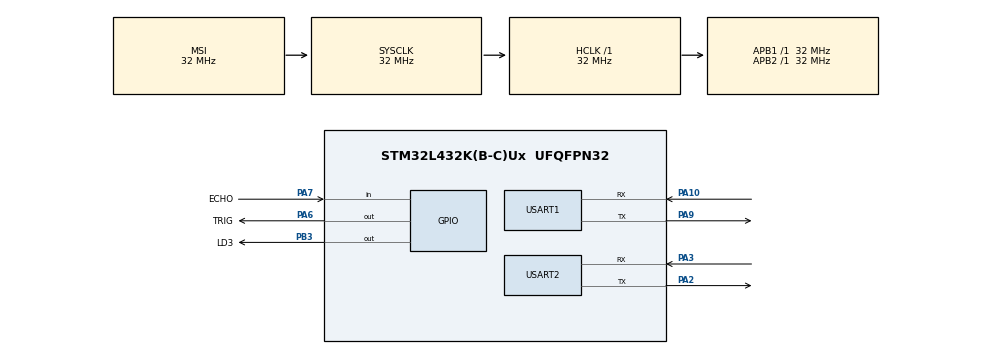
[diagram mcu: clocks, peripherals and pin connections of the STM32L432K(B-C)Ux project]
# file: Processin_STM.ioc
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Mcu.Family=STM32L4
Mcu.Name=STM32L432K(B-C)Ux
Mcu.Package=UFQFPN32
NVIC.PriorityGroup=NVIC_PRIORITYGROUP_4
NVIC.USART2_IRQn=true\:0\:0\:false\:false\:true\:true\:true\:true
PA10.Mode=Asynchronous
PA10.Signal=USART1_RX
PA2.Mode=Asynchronous
PA2.Signal=USART2_TX
PA3.Mode=Asynchronous
PA3.Signal=USART2_RX
PA6.GPIO_Label=TRIG
PA6.Signal=GPIO_Output
PA7.GPIO_Label=ECHO
PA7.Signal=GPIO_Input
PA9.Mode=Asynchronous
PA9.Signal=USART1_TX
PB3\ (JTDO-TRACESWO).GPIO_Label=LD3
PB3\ (JTDO-TRACESWO).Signal=GPIO_Output
ProjectManager.HeapSize=0x200
ProjectManager.StackSize=0x400
ProjectManager.TargetToolchain=CMake
RCC.ADCFreq_Value=128000000
RCC.AHBFreq_Value=32000000
RCC.APB1Freq_Value=32000000
RCC.APB1TimFreq_Value=32000000
RCC.APB2Freq_Value=32000000
RCC.APB2TimFreq_Value=32000000
RCC.CortexFreq_Value=32000000
RCC.HCLKFreq_Value=32000000
RCC.HSE_VALUE=8000000
RCC.HSI48_VALUE=48000000
RCC.HSI_VALUE=16000000
RCC.LSE_VALUE=32768
RCC.MSIClockRange=RCC_MSIRANGE_10
RCC.MSI_VALUE=32000000
RCC.SYSCLKFreq_VALUE=32000000
RCC.USBFreq_Value=128000000
RCC.VCOOutputFreq_Value=256000000
TIM16.Prescaler=31
USART1.VirtualMode-Asynchronous=VM_ASYNC
USART2.VirtualMode-Asynchronous=VM_ASYNC
VP_TIM16_VS_ClockSourceINT.Mode=Enable_Timer
board=custom

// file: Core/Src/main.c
/* USER CODE BEGIN Header */
/**
  ******************************************************************************
  * @file           : main.c
  * @brief          : Main program body
  ******************************************************************************
  * @attention
  *
  * Copyright (c) 2026 STMicroelectronics.
  * All rights reserved.
  *
  * This software is licensed under terms that can be found in the LICENSE file
  * in the root directory of this software component.
  * If no LICENSE file comes with this software, it is provided AS-IS.
  *
  ******************************************************************************
  */
/* USER CODE END Header */
#include "main.h"

/* USER CODE BEGIN Includes */
#include <stdio.h>
#include <string.h>
#include <math.h>
/* USER CODE END Includes */

TIM_HandleTypeDef htim16;

UART_HandleTypeDef huart1;
UART_HandleTypeDef huart2;

void SystemClock_Config(void);
static void MX_GPIO_Init(void);
static void MX_TIM16_Init(void);
static void MX_USART2_UART_Init(void);
static void MX_USART1_UART_Init(void);

int main(void)
{

  /* MCU Configuration--------------------------------------------------------*/

  /* Reset of all peripherals, Initializes the Flash interface and the Systick. */
  HAL_Init();

  /* Configure the system clock */
  SystemClock_Config();

  /* Initialize all configured peripherals */
  MX_GPIO_Init();
  MX_TIM16_Init();
  MX_USART2_UART_Init();
  MX_USART1_UART_Init();
  /* USER CODE BEGIN 2 */
  uint8_t buf[3];
  buf[0] = 128;
  buf[1] = 128;
  uint8_t mean;
  /* USER CODE END 2 */

  /* Infinite loop */
  while (1)
  {
    if (HAL_UART_Receive(&huart1, &buf[2], 1, HAL_MAX_DELAY) == HAL_OK)
    {
        buf[0] = buf[1];
        buf[1] = buf[2];
        mean = (buf[1] + buf[0]) / 2;
        HAL_UART_Transmit(&huart2, &mean, 1, HAL_MAX_DELAY);
    }
  }
}
  /* USER CODE END 3 */

void SystemClock_Config(void)
{
  RCC_OscInitTypeDef RCC_OscInitStruct = {0};
  RCC_ClkInitTypeDef RCC_ClkInitStruct = {0};

  /** Configure the main internal regulator output voltage
  */
  if (HAL_PWREx_ControlVoltageScaling(PWR_REGULATOR_VOLTAGE_SCALE1) != HAL_OK)
  {
    Error_Handler();
  }

  /** Initializes the RCC Oscillators according to the specified parameters
  * in the RCC_OscInitTypeDef structure.
  */
  RCC_OscInitStruct.OscillatorType = RCC_OSCILLATORTYPE_MSI;
  RCC_OscInitStruct.MSIState = RCC_MSI_ON;
  RCC_OscInitStruct.MSICalibrationValue = 0;
  RCC_OscInitStruct.MSIClockRange = RCC_MSIRANGE_10;
  RCC_OscInitStruct.PLL.PLLState = RCC_PLL_NONE;
  if (HAL_RCC_OscConfig(&RCC_OscInitStruct) != HAL_OK)
  {
    Error_Handler();
  }

  /** Initializes the CPU, AHB and APB buses clocks
  */
  RCC_ClkInitStruct.ClockType = RCC_CLOCKTYPE_HCLK|RCC_CLOCKTYPE_SYSCLK
                              |RCC_CLOCKTYPE_PCLK1|RCC_CLOCKTYPE_PCLK2;
  RCC_ClkInitStruct.SYSCLKSource = RCC_SYSCLKSOURCE_MSI;
  RCC_ClkInitStruct.AHBCLKDivider = RCC_SYSCLK_DIV1;
  RCC_ClkInitStruct.APB1CLKDivider = RCC_HCLK_DIV1;
  RCC_ClkInitStruct.APB2CLKDivider = RCC_HCLK_DIV1;

  if (HAL_RCC_ClockConfig(&RCC_ClkInitStruct, FLASH_LATENCY_1) != HAL_OK)
  {
    Error_Handler();
  }
}

static void MX_TIM16_Init(void)
{

  htim16.Instance = TIM16;
  htim16.Init.Prescaler = 31;
  htim16.Init.CounterMode = TIM_COUNTERMODE_UP;
  htim16.Init.Period = 65535;
  htim16.Init.ClockDivision = TIM_CLOCKDIVISION_DIV1;
  htim16.Init.RepetitionCounter = 0;
  htim16.Init.AutoReloadPreload = TIM_AUTORELOAD_PRELOAD_DISABLE;
  if (HAL_TIM_Base_Init(&htim16) != HAL_OK)
  {
    Error_Handler();
  }

}

static void MX_USART1_UART_Init(void)
{

  huart1.Instance = USART1;
  huart1.Init.BaudRate = 115200;
  huart1.Init.WordLength = UART_WORDLENGTH_8B;
  huart1.Init.StopBits = UART_STOPBITS_1;
  huart1.Init.Parity = UART_PARITY_NONE;
  huart1.Init.Mode = UART_MODE_TX_RX;
  huart1.Init.HwFlowCtl = UART_HWCONTROL_NONE;
  huart1.Init.OverSampling = UART_OVERSAMPLING_16;
  huart1.Init.OneBitSampling = UART_ONE_BIT_SAMPLE_DISABLE;
  huart1.AdvancedInit.AdvFeatureInit = UART_ADVFEATURE_NO_INIT;
  if (HAL_UART_Init(&huart1) != HAL_OK)
  {
    Error_Handler();
  }

}

static void MX_USART2_UART_Init(void)
{

  huart2.Instance = USART2;
  huart2.Init.BaudRate = 115200;
  huart2.Init.WordLength = UART_WORDLENGTH_8B;
  huart2.Init.StopBits = UART_STOPBITS_1;
  huart2.Init.Parity = UART_PARITY_NONE;
  huart2.Init.Mode = UART_MODE_TX_RX;
  huart2.Init.HwFlowCtl = UART_HWCONTROL_NONE;
  huart2.Init.OverSampling = UART_OVERSAMPLING_16;
  huart2.Init.OneBitSampling = UART_ONE_BIT_SAMPLE_DISABLE;
  huart2.AdvancedInit.AdvFeatureInit = UART_ADVFEATURE_NO_INIT;
  if (HAL_UART_Init(&huart2) != HAL_OK)
  {
    Error_Handler();
  }

}

static void MX_GPIO_Init(void)
{
  GPIO_InitTypeDef GPIO_InitStruct = {0};

  /* GPIO Ports Clock Enable */
  __HAL_RCC_GPIOA_CLK_ENABLE();
  __HAL_RCC_GPIOB_CLK_ENABLE();

  /*Configure GPIO pin Output Level */
  HAL_GPIO_WritePin(TRIG_GPIO_Port, TRIG_Pin, GPIO_PIN_RESET);

  /*Configure GPIO pin Output Level */
  HAL_GPIO_WritePin(LD3_GPIO_Port, LD3_Pin, GPIO_PIN_RESET);

  /*Configure GPIO pin : TRIG_Pin */
  GPIO_InitStruct.Pin = TRIG_Pin;
  GPIO_InitStruct.Mode = GPIO_MODE_OUTPUT_PP;
  GPIO_InitStruct.Pull = GPIO_NOPULL;
  GPIO_InitStruct.Speed = GPIO_SPEED_FREQ_LOW;
  HAL_GPIO_Init(TRIG_GPIO_Port, &GPIO_InitStruct);

  /*Configure GPIO pin : ECHO_Pin */
  GPIO_InitStruct.Pin = ECHO_Pin;
  GPIO_InitStruct.Mode = GPIO_MODE_INPUT;
  GPIO_InitStruct.Pull = GPIO_NOPULL;
  HAL_GPIO_Init(ECHO_GPIO_Port, &GPIO_InitStruct);

  /*Configure GPIO pin : LD3_Pin */
  GPIO_InitStruct.Pin = LD3_Pin;
  GPIO_InitStruct.Mode = GPIO_MODE_OUTPUT_PP;
  GPIO_InitStruct.Pull = GPIO_NOPULL;
  GPIO_InitStruct.Speed = GPIO_SPEED_FREQ_LOW;
  HAL_GPIO_Init(LD3_GPIO_Port, &GPIO_InitStruct);

}

void Error_Handler(void)
{
  __disable_irq();
  while (1)
  {
  }
}
